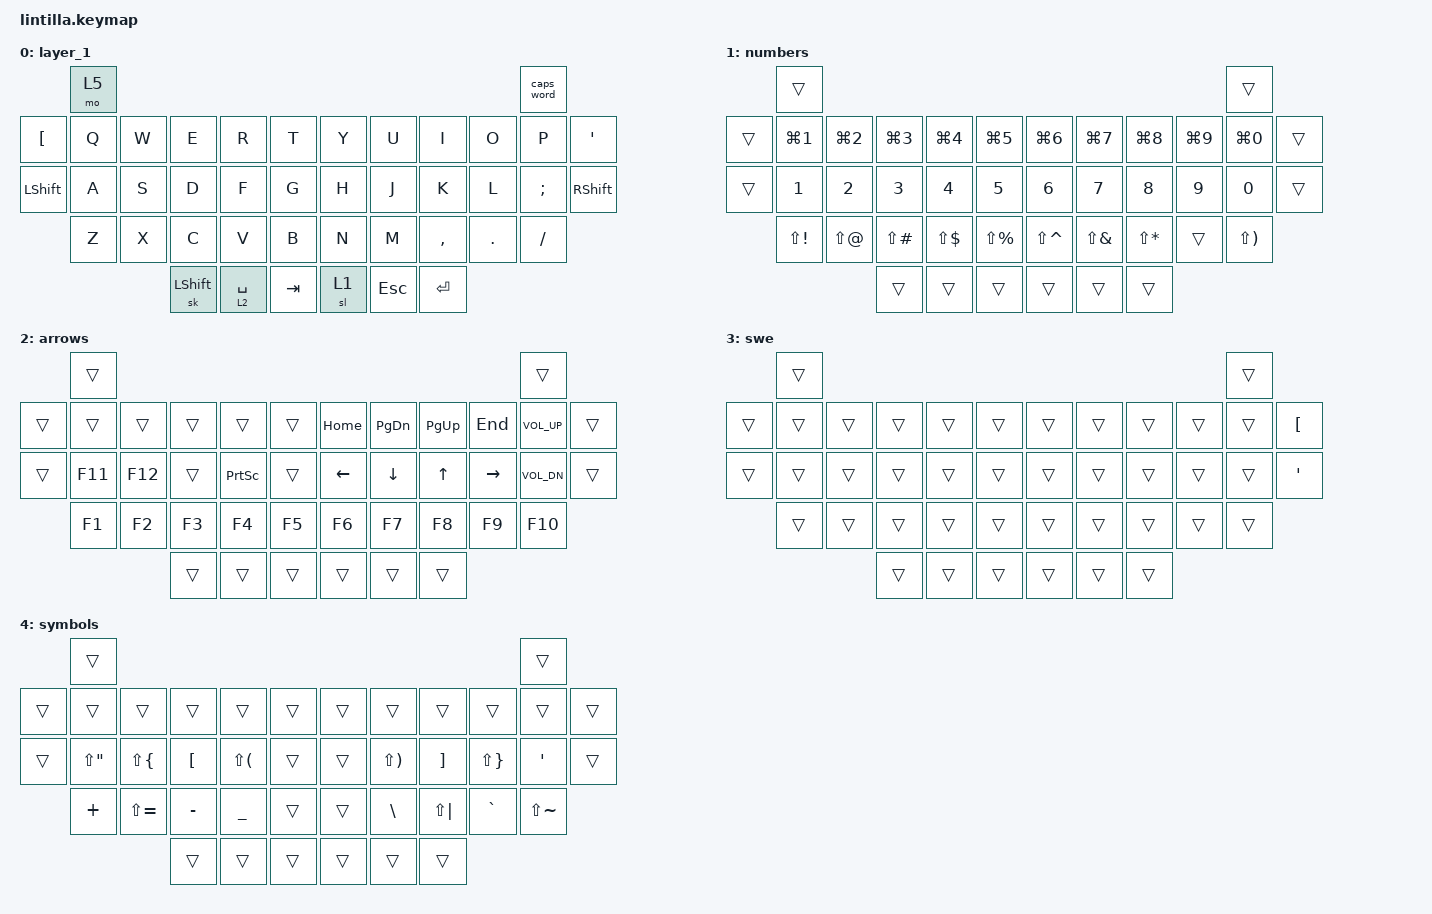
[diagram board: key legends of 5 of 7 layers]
#include <behaviors/rgbled_widget.dtsi>
#include <behaviors.dtsi>
#include <dt-bindings/zmk/bt.h>
#include <dt-bindings/zmk/keys.h>

// Multiple mods

&mt {
    quick-tap-ms = <100>;
    global-quick-tap;
    flavor = "tap-preferred";
    tapping-term-ms = <170>;
};

&sk { quick-release; };

/ {
    combos {
        compatible = "zmk,combos";

        studio_unlock {
            bindings = <&studio_unlock>;
            key-positions = <2 14>;
            require-prior-idle-ms = <200>;
        };

        right_ctrl {
            bindings = <&sk RCTRL>;
            key-positions = <21 22>;
            require-prior-idle-ms = <200>;
        };

        right_gui {
            bindings = <&kp RIGHT_GUI>;
            key-positions = <22 23>;
            require-prior-idle-ms = <200>;
        };

        right_alt {
            bindings = <&kp RIGHT_ALT>;
            key-positions = <23 24>;
            require-prior-idle-ms = <200>;
        };

        backspace {
            bindings = <&kp BACKSPACE>;
            key-positions = <21 23>;
            require-prior-idle-ms = <150>;
        };

        left_control {
            bindings = <&sk LCTRL>;
            key-positions = <18 17>;
            require-prior-idle-ms = <200>;
        };

        left_gui {
            bindings = <&kp LEFT_GUI>;
            key-positions = <16 17>;
            require-prior-idle-ms = <200>;
        };

        left_alt {
            bindings = <&kp LEFT_ALT>;
            key-positions = <15 16>;
            require-prior-idle-ms = <200>;
        };

        delete {
            bindings = <&kp DELETE>;
            key-positions = <16 18>;
            require-prior-idle-ms = <200>;
        };

        sweChar1 {
            bindings = <&kp SQT>;
            key-positions = <28 27>;
        };

        sweChar2 {
            bindings = <&kp LEFT_BRACKET>;
            key-positions = <29 28>;
            require-prior-idle-ms = <0>;
        };

        rightBracket {
            bindings = <&kp RIGHT_BRACKET>;
            key-positions = <32 33>;
            require-prior-idle-ms = <200>;
        };

        minus {
            bindings = <&kp MINUS>;
            key-positions = <34 33>;
            require-prior-idle-ms = <20>;
        };

        left_bracket {
            bindings = <&kp LEFT_PARENTHESIS>;
            key-positions = <29 27>;
            require-prior-idle-ms = <0>;
        };

        right_parantheses {
            bindings = <&kp LS(RIGHT_PARENTHESIS)>;
            key-positions = <34 32>;
            require-prior-idle-ms = <200>;
        };

        left_brace {
            bindings = <&kp LEFT_BRACE>;
            key-positions = <17 29>;
        };

        right_brace {
            bindings = <&kp RIGHT_BRACE>;
            key-positions = <32 22>;
            require-prior-idle-ms = <200>;
        };

        equal {
            bindings = <&kp EQUAL>;
            key-positions = <27 17>;
            require-prior-idle-ms = <200>;
        };

        backslash {
            bindings = <&kp BACKSLASH>;
            key-positions = <34 22>;
            require-prior-idle-ms = <200>;
        };

        graveTilde {
            bindings = <&kp GRAVE>;
            key-positions = <34 35>;
            require-prior-idle-ms = <200>;
        };

        quote {
            bindings = <&kp DOUBLE_QUOTES>;
            key-positions = <4 5>;
            require-prior-idle-ms = <200>;
        };

        underscore {
            bindings = <&kp UNDERSCORE>;
            key-positions = <11 10>;
            require-prior-idle-ms = <50>;
        };
    };

    behaviors {
        shiftCapsWord: shiftCapsWord {
            compatible = "zmk,behavior-tap-dance";
            label = "SHIFTCAPSWORD";
            #binding-cells = <0>;
            bindings = <&sk LEFT_SHIFT>, <&caps_word>;
        };

        navEnter: navEnter {
            compatible = "zmk,behavior-hold-tap";
            label = "NAVENTER";
            bindings = <&mo>, <&kp>;

            #binding-cells = <2>;
            tapping-term-ms = <500>;
            retro-tap;
        };

        urubLayerTap: urubLayerTap {
            compatible = "zmk,behavior-hold-tap";
            label = "URUBLAYERTAP";
            bindings = <&mo>, <&kp>;

            #binding-cells = <2>;
            tapping-term-ms = <250>;
            require-prior-idle-ms = <150>;
            flavor = "balanced";
        };

        tapDanceShift: tapDanceShift {
            compatible = "zmk,behavior-tap-dance";
            label = "TAPDANCESHIFT";
            #binding-cells = <0>;
            bindings = <&sk LEFT_SHIFT>, <&caps_word>;
        };
    };

    keymap {
        compatible = "zmk,keymap";

        layer_1 {
            bindings = <
                  &mo 5                                                                                                 &caps_word
&kp LEFT_BRACKET  &kp Q  &kp W  &kp E           &kp R                  &kp T    &kp Y  &kp U       &kp I       &kp O    &kp P       &kp SQT
&kp LSHFT         &kp A  &kp S  &kp D           &kp F                  &kp G    &kp H  &kp J       &kp K       &kp L    &kp SEMI    &kp RSHFT
                  &kp Z  &kp X  &kp C           &kp V                  &kp B    &kp N  &kp M       &kp COMMA   &kp DOT  &kp FSLH
                                &sk LEFT_SHIFT  &urubLayerTap 2 SPACE  &kp TAB  &sl 1  &kp ESCAPE  &kp RETURN
            >;
        };

        numbers {
            bindings = <
        &trans                                                                                                                       &trans
&trans  &kp LG(N1)    &kp LG(N2)  &kp LG(N3)     &kp LG(N4)    &kp LG(N5)     &kp LG(N6)     &kp LG(N7)    &kp LG(N8)    &kp LG(N9)  &kp LG(N0)    &trans
&trans  &kp N1        &kp N2      &kp N3         &kp N4        &kp N5         &kp N6         &kp N7        &kp N8        &kp N9      &kp N0        &trans
        &kp LS(EXCL)  &kp LS(AT)  &kp LS(POUND)  &kp LS(DLLR)  &kp LS(PRCNT)  &kp LS(CARET)  &kp LS(AMPS)  &kp LS(STAR)  &trans      &kp LS(RPAR)
                                  &trans         &trans        &trans         &trans         &trans        &trans
            >;
        };

        arrows {
            bindings = <
        &trans                                                                                              &trans
&trans  &trans   &trans   &trans  &trans           &trans  &kp HOME  &kp PAGE_DOWN  &kp PAGE_UP  &kp END    &kp C_VOLUME_UP  &trans
&trans  &kp F11  &kp F12  &trans  &kp PRINTSCREEN  &trans  &kp LEFT  &kp DOWN       &kp UP       &kp RIGHT  &kp C_VOL_DN     &trans
        &kp F1   &kp F2   &kp F3  &kp F4           &kp F5  &kp F6    &kp F7         &kp F8       &kp F9     &kp F10
                          &trans  &trans           &trans  &trans    &trans         &trans
            >;
        };

        swe {
            bindings = <
        &trans                                                                  &trans
&trans  &trans  &trans  &trans  &trans  &trans  &trans  &trans  &trans  &trans  &trans  &kp LEFT_BRACKET
&trans  &trans  &trans  &trans  &trans  &trans  &trans  &trans  &trans  &trans  &trans  &kp SQT
        &trans  &trans  &trans  &trans  &trans  &trans  &trans  &trans  &trans  &trans
                        &trans  &trans  &trans  &trans  &trans  &trans
            >;
        };

        symbols {
            bindings = <
        &trans                                                                                                           &trans
&trans  &trans       &trans         &trans     &trans          &trans  &trans  &trans        &trans        &trans        &trans         &trans
&trans  &kp LS(DQT)  &kp LS(LBRC)   &kp LBKT   &kp LS(LPAR)    &trans  &trans  &kp LS(RPAR)  &kp RBKT      &kp LS(RBRC)  &kp SQT        &trans
        &kp PLUS     &kp LS(EQUAL)  &kp MINUS  &kp UNDERSCORE  &trans  &trans  &kp BSLH      &kp LS(PIPE)  &kp GRAVE     &kp LS(TILDE)
                                    &trans     &trans          &trans  &trans  &trans        &trans
            >;
        };

        bluetooth {
            bindings = <
                &trans                                                                                          &trans
&bt BT_CLR      &trans  &bt BT_SEL 3  &bt BT_SEL 2  &bt BT_SEL 1  &bt BT_SEL 0  &trans  &trans  &trans  &trans  &trans  &trans
&bt BT_CLR_ALL  &trans  &trans        &trans        &trans        &trans        &trans  &trans  &trans  &trans  &trans  &trans
                &trans  &trans        &trans        &trans        &trans        &trans  &trans  &trans
                                      &trans        &trans        &trans        &trans  &trans  &trans
            >;
        };

        layer_6 {
            bindings = <
        &trans                                                                  &trans
&trans  &trans  &trans  &trans  &trans  &trans  &trans  &trans  &trans  &trans  &trans  &trans
&trans  &trans  &trans  &trans  &trans  &trans  &trans  &trans  &trans  &trans  &trans  &trans
        &trans  &trans  &trans  &trans  &trans  &trans  &trans  &trans  &trans
                        &trans  &trans  &trans  &trans  &trans  &trans
            >;
        };
    };
};

// vim: expandtab softtabstop=4 shiftwidth=4 filetype=dts
